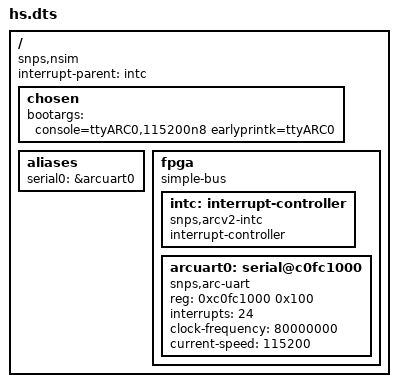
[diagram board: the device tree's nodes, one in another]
/*
 * Copyright (C) 2013 Synopsys, Inc. (www.synopsys.com)
 *
 * This program is free software; you can redistribute it and/or modify
 * it under the terms of the GNU General Public License version 2 as
 * published by the Free Software Foundation.
 */
/dts-v1/;

/include/ "skeleton.dtsi"

/ {
	compatible = "snps,nsim";
	interrupt-parent = <&intc>;

	chosen {
		bootargs = "console=ttyARC0,115200n8 earlyprintk=ttyARC0";
	};

	aliases {
		serial0 = &arcuart0;
	};

	fpga {
		compatible = "simple-bus";
		#address-cells = <1>;
		#size-cells = <1>;

		/* child and parent address space 1:1 mapped */
		ranges;

		intc: interrupt-controller {
			compatible = "snps,arcv2-intc";
			interrupt-controller;
			#interrupt-cells = <1>;
		};

		arcuart0: serial@c0fc1000 {
			compatible = "snps,arc-uart";
			reg = <0xc0fc1000 0x100>;
			interrupts = <24>;
			clock-frequency = <80000000>;
			current-speed = <115200>;
			status = "okay";
		};
	};
};
